# nrf9120_mlm1_modem register map
Vendor: Nordic Semiconductor; Series: nrf91; File version: 1
CPU: CM4 r0p1, little endian, MPU, no FPU, 3 interrupt priority bits
Registers are 32-bit, read-write, reset 0x0 unless marked. A register's access mark holds for its fields unless they carry their own. Offsets are from the block's base; [hi:lo] are bit positions; {n}, {i} and the like mark numbered series; 'fields as' and 'values as' point back to an identical list.

## SECCONTROL — Secure Control
Base 0x40032000
0x400 OTPTOPADDR write-once reset 0x8000 — Top address of the OTP area. Address must be divisible by four
  [31:0] OTPTOPADDR — Top address of the OTP area. This register type is WRITE ONCE.
0x404 SECUREEXIT wo — Writing to this register will enable secure exit.
  [15:0] SECUREEXIT
    0=SECUREEXIT (Secure Exit disabled. Secure Exit enabled.)
0x408 SNOOPENABLE — Enable SecureEntry snooping.
  [0] SNOOPENABLE
    0=Disabled (Secure Entry sequence snooping disabled.); 1=Enabled (Secure Entry sequence snooping enabled.)
0x40C SECWRENABLERANGE reset 0xFFFFFFFF — FICR Wr enable range.
  [31:0] SECWREABLERANGE
0x410 AESDMAPROMOTION — AES DMA promoted as a secure device.
  [0] AESDMAPROMOTION — AES DMA promotion as a secure device.
    0=Nonsecure (AES DMA is a nonsecure device.); 1=Secure (AES DMA is a secure device.)
0x414 SHADMAPROMOTION — SHA DMA promoted as a secure device.
  [0] SHADMAPROMOTION — SHA DMA promotion as a secure device.
    values as AESDMAPROMOTION.AESDMAPROMOTION
0x418 SECUREWATCHDOGPAUSE — Secure watchdog pause control.
  [0] SECUREWDPAUSE
    0=Running (Secure WD running.); 1=Paused (Secure WD paused.)

## TIMEMARKMUX — Timemark multiplexer for LTE System Timer
Base 0x40033000
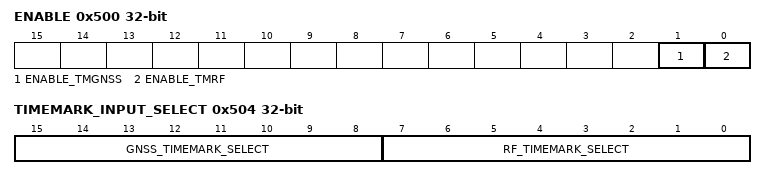
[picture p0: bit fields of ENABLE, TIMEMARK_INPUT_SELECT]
0x500 ENABLE — Enable Timemark Mux
  [1] ENABLE_TMGNSS — Enable
    0=Disable GNSS timemark output; 1=Enable GNSS timemark output
  [0] ENABLE_TMRF — Enable
    0=Disable RF timemark output; 1=Enable RF timemark output
0x504 TIMEMARK_INPUT_SELECT
  [15:8] GNSS_TIMEMARK_SELECT — GNSS timemark input select
    1=Event0 (Enable events[0] as timemark input); 2=Event1 (Enable events[1] as timemark input); 4=Event2 (Enable events[2] as timemark input); 8=Event3 (Enable events[3] as timemark input); 16=Event4 (Enable events[4] as timemark input); 32=Event5 (Enable events[5] as timemark input); 64=Event6 (Enable events[6] as timemark input); 128=Event7 (Enable events[7] as timemark input)
  [7:0] RF_TIMEMARK_SELECT — RF timemark input select
    values as GNSS_TIMEMARK_SELECT

## TIMEREVENTSYNC — Timer event synchronizer
Base 0x40035000
0x00 CLOCKENABLE — Enable synchronizer clock.
  [0] CLOCKENABLE — Enable.
    0=Disable clock; 1=Enable clock

## TEMP — Temperature Sensor
Base 0x40039000
0x00 TASKS_START wo — Start temperature measurement
  [0] TASKS_START
    1=Trigger task
0x04 TASKS_STOP wo — Stop temperature measurement
  [0] TASKS_STOP
    1=Trigger task
0x100 EVENTS_DATARDY — Temperature measurement complete, data ready
  [0] EVENTS_DATARDY
    0=NotGenerated (Event not generated); 1=Generated (Event generated)
0x300 INTEN — Enable or disable interrupt
  [0] DATARDY — Enable or disable interrupt for event DATARDY
    0=Disabled; 1=Enabled
0x304 INTENSET — Enable interrupt
  [0] DATARDY — Write '1' to enable interrupt for event DATARDY
    on read: 0=Disabled (Read: Disabled); 1=Enabled (Read: Enabled) | on write: 1=Set (Enable)
0x308 INTENCLR — Disable interrupt
  [0] DATARDY — Write '1' to disable interrupt for event DATARDY
    on read: 0=Disabled (Read: Disabled); 1=Enabled (Read: Enabled) | on write: 1=Clear (Disable)
0x508 TEMP ro — Temperature in degC (0.25deg steps)
0x510 DATA ro — Data after dec and calib
  [12:0] DATA
0x514 CALIB reset 0x182 — Calibration value. Reset value is taken from FICR->CHIPCONF01 bit 31:22
  [9:0] CALIB
0x520 A0 reset 0x326 — Slope of 1st piece wise linear function
  [11:0] A0
0x524 A1 reset 0x348 — Slope of 2nd piece wise linear function
  [11:0] A1
0x528 A2 reset 0x3AA — Slope of 3rd piece wise linear function
  [11:0] A2
0x52C A3 reset 0x40E — Slope of 4th piece wise linear function
  [11:0] A3
0x530 A4 reset 0x4BD — Slope of 5th piece wise linear function
  [11:0] A4
0x534 A5 reset 0x5A3 — Slope of 6th piece wise linear function
  [11:0] A5
0x540 B0 reset 0x3FEF — y-intercept of 1st piece wise linear function
  [13:0] B0
0x544 B1 reset 0x3FBE — y-intercept of 2nd piece wise linear function
  [13:0] B1
0x548 B2 reset 0x3FBE — y-intercept of 3rd piece wise linear function
  [13:0] B2
0x54C B3 reset 0x12 — y-intercept of 4th piece wise linear function
  [13:0] B3
0x550 B4 reset 0x124 — y-intercept of 5th piece wise linear function
  [13:0] B4
0x554 B5 reset 0x27C — y-intercept of 6th piece wise linear function
  [13:0] B5
0x560 T0 reset 0xE2 — End point of 1st piece wise linear function
  [7:0] T0
0x564 T1 — End point of 2nd piece wise linear function
  [7:0] T1
0x568 T2 reset 0x19 — End point of 3rd piece wise linear function
  [7:0] T2
0x56C T3 reset 0x3C — End point of 4th piece wise linear function
  [7:0] T3
0x570 T4 reset 0x50 — End point of 5th piece wise linear function
  [7:0] T4
0xFFC POWER reset 0x1 — Peripheral power control
  [0] POWER — Peripheral power control. The peripheral and its registers will be reset to its initial state by switching the peripheral off and then back on again.
    0=Disabled (Peripheral is powered off); 1=Enabled (Peripheral is powered on)

## BPROT — Block Protect
Base 0x40060000
0x704 DISABLEINDEBUG reset 0x1 — Disable protection mechanism in debug mode
  [0] DISABLEINDEBUG — Disable the protection mechanism for NVM regions while in debug mode. This register will only disable the protection mechanism if the device is in debug mode.
    1=Disabled (Disable in debug); 0=Enabled (Enable in debug)
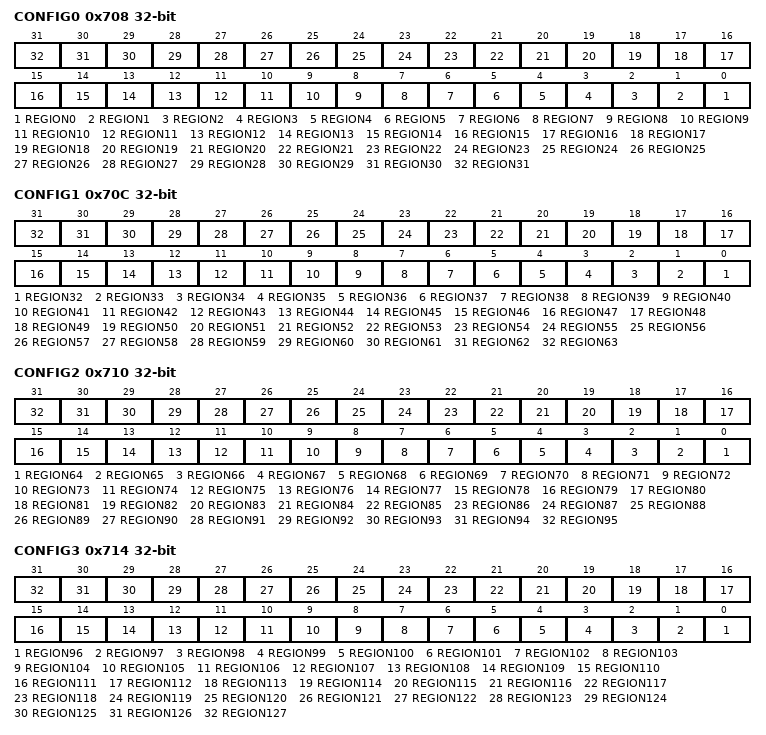
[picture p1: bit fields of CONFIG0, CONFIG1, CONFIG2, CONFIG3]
0x708 CONFIG0 — Block protect configuration register 0
  [all] fields
    0=Disabled (Protection disabled); 1=Enabled (Protection enable)
  [n] REGION{n} (n=0..31) — Enable protection for region {n}. Write '0' has no effect.
0x70C CONFIG1 — Block protect configuration register 0
  [all] fields
    values as the fields of CONFIG0
  [n-32] REGION{n} (n=32..63) — Enable protection for region {n}. Write '0' has no effect.
0x710 CONFIG2 — Block protect configuration register 0
  [all] fields
    values as the fields of CONFIG0
  [n-64] REGION{n} (n=64..95) — Enable protection for region {n}. Write '0' has no effect.
0x714 CONFIG3 — Block protect configuration register 0
  [all] fields
    values as the fields of CONFIG0
  [n-96] REGION{n} (n=96..127) — Enable protection for region {n}. Write '0' has no effect.
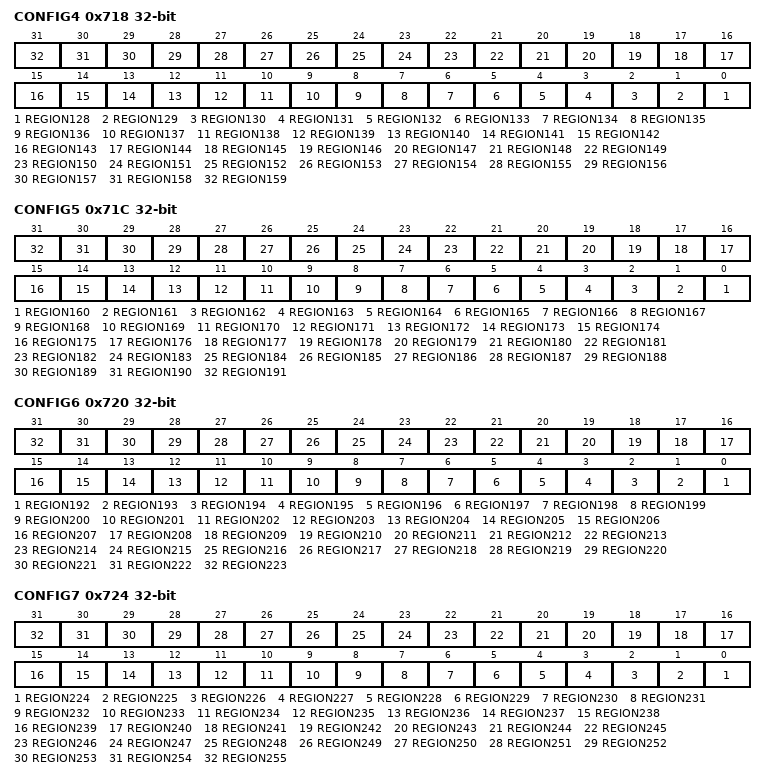
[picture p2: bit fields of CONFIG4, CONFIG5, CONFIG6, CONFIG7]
0x718 CONFIG4 — Block protect configuration register 0
  [all] fields
    values as the fields of CONFIG0
  [n-128] REGION{n} (n=128..159) — Enable protection for region {n}. Write '0' has no effect.
0x71C CONFIG5 — Block protect configuration register 0
  [all] fields
    values as the fields of CONFIG0
  [n-160] REGION{n} (n=160..191) — Enable protection for region {n}. Write '0' has no effect.
0x720 CONFIG6 — Block protect configuration register 0
  [all] fields
    values as the fields of CONFIG0
  [n-192] REGION{n} (n=192..223) — Enable protection for region {n}. Write '0' has no effect.
0x724 CONFIG7 — Block protect configuration register 0
  [all] fields
    values as the fields of CONFIG0
  [n-224] REGION{n} (n=224..255) — Enable protection for region {n}. Write '0' has no effect.
